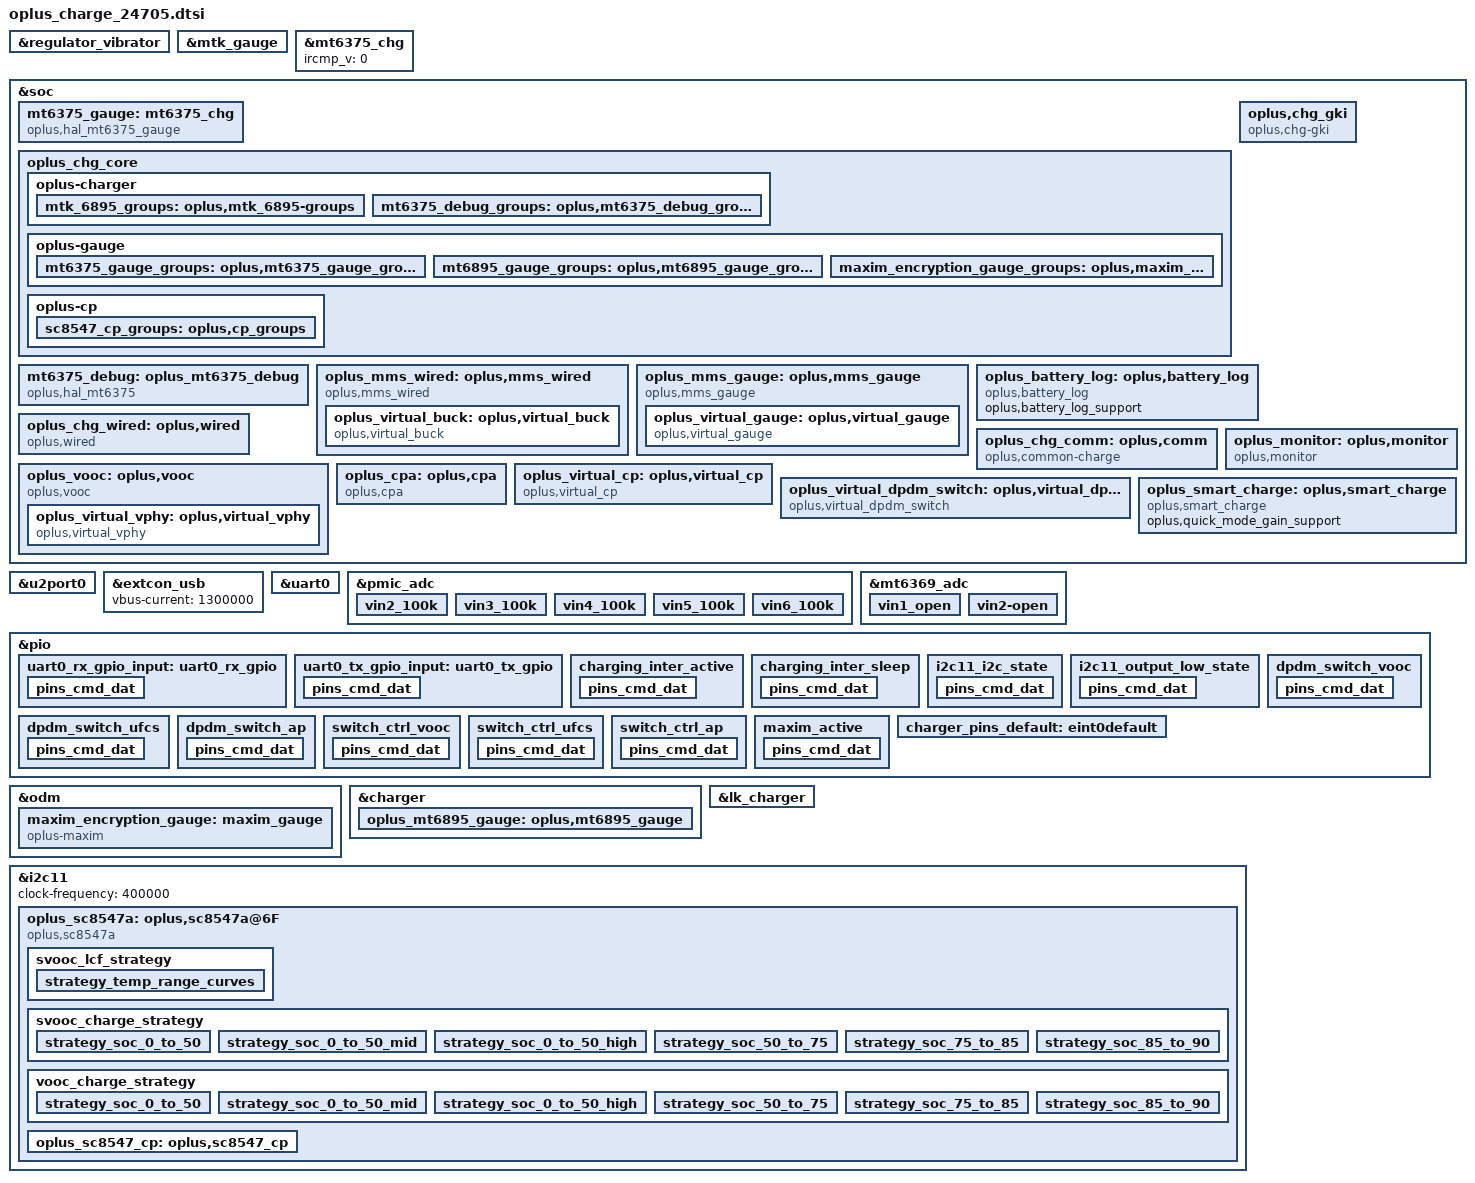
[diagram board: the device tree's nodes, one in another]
// SPDX-License-Identifier: GPL-2.0-only
/*
* Copyright (C) 2021-2020 Oplus. All rights reserved.
*/
#include <dt-bindings/iio/mt635x-auxadc.h>
#include <dt-bindings/iio/adc/mediatek,mt6375_auxadc.h>
#include <dt-bindings/pinctrl/mt6373-pinfunc.h>
#include <dt-bindings/pinctrl/mt65xx.h>
#include "oplus_chg.h"

/*
 *
 * CPU:MT6878 CASIO
 *
 * UTXD0 -->GPIO48
 * URXD0 -->GPIO49
 *
 * I2C
 * MASTER_CHG --> I2C5 MT6375
 * CP_MASTER  --> I2C11 SC8547B
 * CP_SLAVE   --> I2C9 SC8547B
 *
 * IRQB
 * EINT_CHG_1 (cp1 irq)               -->GPIO8
 * EINT_CHG_2 (cp2 irq)               -->GPIO9
 *
 * GPIO
 * VBUS_SHORT(防烧口)                 --> MT6369 MOS_CON1 H8
 * USB_SWITCH_1(usb/uart&vooc switch) --> GPIO44
 * USB_SWITCH_2(uart/vooc switch)     --> GPIO153
 * SEC_IC (加密电池GPIO for 80W)      --> GPIO43
 *
 * ADC:
 * MT6369 AUXADC_VIN1 				--> VBAT_BTB (Battery BTB)
 * MT6369 AUXADC_VIN2               --> NTC_USBCON_TEM (USB BTB)
 *
 * MT6363 AUXADC_VIN2				--> BAT_ID_ADC 电池ID
 * MT6363 AUXADC_VIN3				--> BATThermal_1 小板NTC
 * MT6363 AUXADC_VIN4				--> BB_USB_ADC1 防烧口NTC1
 * MT6363 AUXADC_VIN5				--> BB_USB_ADC2 防烧口NTC2
 * MT6363 AUXADC_VIN6				--> NTC_CHARGE (充电IC旁)
 *
 */

/* charge start */
&regulator_vibrator{
	min-volt = <2800000>;
	max-volt = <2800000>;
};

&mtk_gauge {
	status = "okay";
	charger = <&mt6375_chg>;
	FUELGAGUE_APPLY = <(1)>;
	IS_SUBBOARD_TEMP_SUPPORT = <(0)>;
	EXTERNAL_AUTHENTICATE =<(1)>;
	Enable_Is_Force_Full = <(1)>;
	active-table = <(5)>;
	r-fg-value = <(5)>;/* R_sense resistance. 2 milliohm */
	com-r-fg-value = <(0)>;/* R_sense compensate resistance. not use COM_R_FG_VALUE */
	UNIT_MULTIPLE = <(1)>;
	RBAT_PULL_DOWN_R = <(24000)>;
	RBAT_PULL_UP_R = <(12000)>;
	RBAT_PULL_UP_VOLT = <(1840)>;
	USE_MORE_PRECISE_NTC_TABLE = <(1)>;
	car-tune-value = <(98)>;
	SHUTDOWN_1_TIME = <(5)>;

	io-channels = <&mt6375_auxadc MT6375_AUXADC_BATSNS>,
				  <&mt6375_auxadc MT6375_AUXADC_BATON>,
				  <&mt6375_auxadc MT6375_AUXADC_IMP>,
				  <&mt6375_auxadc MT6375_AUXADC_IMIX_R>,
				  <&mt6375_auxadc MT6375_AUXADC_VREF>,
				  <&pmic_adc AUXADC_VIN2>;
	io-channel-names = "bat_volt", "bat_temp", "ptim_bat_volt",
					   "ptim_r", "vref", "auxadc5-batt_id_v";

	#include "bat_setting/mt6878_battery_prop_dim2_ext_24705.dtsi"
	#include "bat_setting/mt6878_battery_table_24705.dtsi"
};

&mt6375_chg {
	ircmp_v = <0>;
};

&soc {
	mt6375_gauge: mt6375_chg {
		status = "okay";
		compatible = "oplus,hal_mt6375_gauge";

		oplus,ic_type = <OPLUS_CHG_IC_GAUGE>;
		oplus,ic_index = <0>;
		oplus,batt_num = <1>;
		oplus,mtk_gauge_power_sel_support;
	};
};

&u2port0 {
	mediatek,eye-vrt = <7>;
	mediatek,eye-term = <7>;
	mediatek,rev6 = <3>;
	mediatek,eye-vrt-host = <7>;
	mediatek,eye-term-host = <2>;
	mediatek,rev6-host = <3>;
	mediatek,discth = <0x9>;
};

&extcon_usb {
	vbus-current = <1300000>;
};

&uart0 {
	pinctrl-names = "uart0_rx_gpio", "uart0_tx_gpio";
	pinctrl-0 = <&uart0_rx_gpio_input>;
	pinctrl-1 = <&uart0_tx_gpio_input>;
	status = "okay";
	txpin = <48>;
	rxpin = <49>;
};

&pmic_adc {
	vin2_100k {
		channel = <AUXADC_VIN2>;
		pures = <ADC_PURES_100K>;
	};
	vin3_100k {
		channel = <AUXADC_VIN3>;
		pures = <ADC_PURES_100K>;
	};
	vin4_100k {
		channel = <AUXADC_VIN4>;
		pures = <ADC_PURES_100K>;
	};
	vin5_100k {
		channel = <AUXADC_VIN5>;
		pures = <ADC_PURES_100K>;
	};
	vin6_100k {
		channel = <AUXADC_VIN6>;
		pures = <ADC_PURES_100K>;
	};
};

&mt6369_adc {
    vin1_open {
		channel = <AUXADC_VIN1>;
		pures = <ADC_PURES_OPEN>;
    };
	vin2-open {
		channel = <AUXADC_VIN2>;
		pures = <ADC_PURES_OPEN>;
	};
};

&pio {
	uart0_rx_gpio_input: uart0_rx_gpio {
		pins_cmd_dat {
			pinmux = <PINMUX_GPIO49__FUNC_GPIO49>; /* URXD0 */
			input-enable;
			bias-disable;
		};
	};

	uart0_tx_gpio_input: uart0_tx_gpio {
		pins_cmd_dat {
			pinmux = <PINMUX_GPIO48__FUNC_GPIO48>; /* UTXD0 */
			input-enable;
			bias-disable;
		};
	};

	charging_inter_active: charging_inter_active {
		pins_cmd_dat {
			pinmux = <PINMUX_GPIO8__FUNC_GPIO8>;
			input-enable;
			bias-pull-up;
		};
	};

	charging_inter_sleep: charging_inter_sleep {
		pins_cmd_dat {
			pinmux = <PINMUX_GPIO8__FUNC_GPIO8>;
			input-enable;
			bias-pull-up;
		};
	};

	i2c11_i2c_state: i2c11_i2c_state {
		pins_cmd_dat {
			pinmux = <PINMUX_GPIO148__FUNC_SDA11>,
				 <PINMUX_GPIO147__FUNC_SCL11>;
			bias-disable;
		};
	};

	i2c11_output_low_state: i2c11_output_low_state {
		pins_cmd_dat {
			pinmux = <PINMUX_GPIO148__FUNC_GPIO148>,
				 <PINMUX_GPIO147__FUNC_GPIO147>;
			output-low;
		};
	};

	dpdm_switch_vooc: dpdm_switch_vooc {
		pins_cmd_dat {
			pinmux = <PINMUX_GPIO44__FUNC_GPIO44>;
			output-high;
		};
 	};

 	dpdm_switch_ufcs: dpdm_switch_ufcs {
 		pins_cmd_dat {
			pinmux = <PINMUX_GPIO44__FUNC_GPIO44>;
			output-high;
		};
 	};

 	dpdm_switch_ap: dpdm_switch_ap {
 		pins_cmd_dat {
			pinmux = <PINMUX_GPIO44__FUNC_GPIO44>;
			output-low;
		};
 	};

 	switch_ctrl_vooc: switch_ctrl_vooc {
 		pins_cmd_dat {
			pinmux = <PINMUX_GPIO153__FUNC_GPIO153>;
			output-high;
		};
 	};

 	switch_ctrl_ufcs: switch_ctrl_ufcs {
 		pins_cmd_dat {
			pinmux = <PINMUX_GPIO153__FUNC_GPIO153>;
			output-high;
		};
 	};

 	switch_ctrl_ap: switch_ctrl_ap {
 		pins_cmd_dat {
			pinmux = <PINMUX_GPIO153__FUNC_GPIO153>;
			output-low;
		};
 	};

	maxim_active: maxim_active {
		pins_cmd_dat {
			pinmux = <PINMUX_GPIO43__FUNC_GPIO43>;
			drive-strength = <6>;
			bias-pull-up;
		};
	};

	charger_pins_default: eint0default {
	};
};

&soc {
	oplus_chg_core {
		oplus,chg_framework_v2;
		oplus,smart_charging_screenoff;
		oplus,chg_spec_version = <OPLUS_CHG_SPEC_VER_V3P7>;

		oplus-charger {
			mtk_6895_groups: oplus,mtk_6895-groups {
				functions = <
					OPLUS_IC_FUNC_INIT
					OPLUS_IC_FUNC_EXIT
					OPLUS_IC_FUNC_REG_DUMP
					OPLUS_IC_FUNC_SMT_TEST
					OPLUS_IC_FUNC_BUCK_INPUT_PRESENT
					OPLUS_IC_FUNC_BUCK_INPUT_SUSPEND
					OPLUS_IC_FUNC_BUCK_INPUT_IS_SUSPEND
					OPLUS_IC_FUNC_BUCK_OUTPUT_SUSPEND
					OPLUS_IC_FUNC_BUCK_OUTPUT_IS_SUSPEND
					OPLUS_IC_FUNC_BUCK_SET_ICL
					OPLUS_IC_FUNC_BUCK_GET_ICL
					OPLUS_IC_FUNC_BUCK_SET_FCC
					OPLUS_IC_FUNC_BUCK_SET_FV
					OPLUS_IC_FUNC_BUCK_SET_ITERM
					OPLUS_IC_FUNC_BUCK_GET_INPUT_CURR
					OPLUS_IC_FUNC_BUCK_GET_INPUT_VOL
					OPLUS_IC_FUNC_OTG_BOOST_ENABLE
					OPLUS_IC_FUNC_BUCK_GET_CC_ORIENTATION
					OPLUS_IC_FUNC_BUCK_GET_CHARGER_TYPE
					OPLUS_IC_FUNC_BUCK_RERUN_BC12
					OPLUS_IC_FUNC_BUCK_QC_DETECT_ENABLE
					OPLUS_IC_FUNC_BUCK_SET_QC_CONFIG
					OPLUS_IC_FUNC_BUCK_SET_PD_CONFIG
					OPLUS_IC_FUNC_GET_SHUTDOWN_SOC
					OPLUS_IC_FUNC_BACKUP_SOC
					OPLUS_IC_FUNC_GET_TYPEC_MODE
					OPLUS_IC_FUNC_SET_TYPEC_MODE
					OPLUS_IC_FUNC_GET_TYPEC_ROLE
					OPLUS_IC_FUNC_GET_OTG_ENABLE
					OPLUS_IC_FUNC_BUCK_GET_HW_DETECT
					OPLUS_IC_FUNC_SET_USB_DISCHG_ENABLE
					OPLUS_IC_FUNC_GET_USB_DISCHG_STATUS
					OPLUS_IC_FUNC_IS_OPLUS_SVID
					OPLUS_IC_FUNC_BUCK_GET_USB_BTB_TEMP
					OPLUS_IC_FUNC_BUCK_GET_BATT_BTB_TEMP
					OPLUS_IC_FUNC_BUCK_SHIPMODE_ENABLE
					OPLUS_IC_FUNC_BUCK_SET_AICL_POINT
					OPLUS_IC_FUNC_SET_OTG_BOOST_CURR_LIMIT
					OPLUS_IC_FUNC_BUCK_GET_FV
					OPLUS_IC_FUNC_BUCK_GET_TYPEC_STATE
				>;
				virqs = <
					OPLUS_IC_VIRQ_ERR
					OPLUS_IC_VIRQ_CC_DETECT
					OPLUS_IC_VIRQ_PLUGIN
					OPLUS_IC_VIRQ_CC_CHANGED
					OPLUS_IC_VIRQ_CHG_TYPE_CHANGE
					OPLUS_IC_VIRQ_OTG_ENABLE
					OPLUS_IC_VIRQ_SVID
					OPLUS_IC_VIRQ_TYPEC_STATE
				>;
			};


			mt6375_debug_groups: oplus,mt6375_debug_groups {
				functions = <
					OPLUS_IC_FUNC_INIT
					OPLUS_IC_FUNC_EXIT
				>;
				virqs = <
					OPLUS_IC_VIRQ_ERR
				>;
			};
		};

		oplus-gauge {
			mt6375_gauge_groups: oplus,mt6375_gauge_groups {
				functions = <
					OPLUS_IC_FUNC_INIT
					OPLUS_IC_FUNC_EXIT
					OPLUS_IC_FUNC_REG_DUMP
					OPLUS_IC_FUNC_SMT_TEST
					OPLUS_IC_FUNC_GAUGE_GET_BATT_VOL
					OPLUS_IC_FUNC_GAUGE_GET_BATT_MAX
					OPLUS_IC_FUNC_GAUGE_GET_BATT_MIN
					OPLUS_IC_FUNC_GAUGE_GET_BATT_CURR
					OPLUS_IC_FUNC_GAUGE_GET_BATT_TEMP
					OPLUS_IC_FUNC_GAUGE_GET_BATT_SOC
					OPLUS_IC_FUNC_GAUGE_GET_BATT_FCC
					OPLUS_IC_FUNC_GAUGE_GET_BATT_CC
					OPLUS_IC_FUNC_GAUGE_GET_BATT_RM
					OPLUS_IC_FUNC_GAUGE_GET_BATT_SOH
					OPLUS_IC_FUNC_GAUGE_GET_BATT_HMAC
					OPLUS_IC_FUNC_GAUGE_SET_BATT_FULL
					OPLUS_IC_FUNC_GAUGE_UPDATE_DOD0
					OPLUS_IC_FUNC_GAUGE_UPDATE_SOC_SMOOTH
					OPLUS_IC_FUNC_GAUGE_GET_CB_STATUS
					OPLUS_IC_FUNC_GAUGE_GET_BATT_NUM
					OPLUS_IC_FUNC_GAUGE_GET_DEVICE_TYPE
					OPLUS_IC_FUNC_GAUGE_GET_DEVICE_TYPE_FOR_VOOC
					OPLUS_IC_FUNC_GAUGE_GET_BATT_FCC
					OPLUS_IC_FUNC_GAUGE_GET_BATT_FC
					OPLUS_IC_FUNC_GAUGE_GET_BATT_QM
					OPLUS_IC_FUNC_GAUGE_GET_BATT_PD
					OPLUS_IC_FUNC_GAUGE_GET_BATT_RCU
					OPLUS_IC_FUNC_GAUGE_GET_BATT_RCF
					OPLUS_IC_FUNC_GAUGE_GET_BATT_FCU
					OPLUS_IC_FUNC_GAUGE_GET_BATT_FCF
					OPLUS_IC_FUNC_GAUGE_GET_BATT_SOU
					OPLUS_IC_FUNC_GAUGE_GET_BATT_DO0
					OPLUS_IC_FUNC_GAUGE_GET_BATT_DOE
					OPLUS_IC_FUNC_GAUGE_GET_BATT_TRM
					OPLUS_IC_FUNC_GAUGE_GET_BATT_PC
					OPLUS_IC_FUNC_GAUGE_GET_BATT_QS
					OPLUS_IC_FUNC_GAUGE_IS_SUSPEND
					OPLUS_IC_FUNC_GAUGE_GET_BCC_PARMS
					OPLUS_IC_FUNC_GAUGE_FASTCHG_UPDATE_BCC_PARMS
					OPLUS_IC_FUNC_GAUGE_GET_PREV_BCC_PARMS
					OPLUS_IC_FUNC_GAUGE_SET_BCC_PARMS
					OPLUS_IC_FUNC_GAUGE_SET_PROTECT_CHECK
					OPLUS_IC_FUNC_GAUGE_GET_AFI_UPDATE_DONE
					OPLUS_IC_FUNC_GAUGE_CHECK_RESET
					OPLUS_IC_FUNC_GAUGE_GET_DEVICE_TYPE_FOR_BCC
					OPLUS_IC_FUNC_GAUGE_GET_DOD0
					OPLUS_IC_FUNC_GAUGE_GET_DOD0_PASSED_Q
					OPLUS_IC_FUNC_GAUGE_GET_QMAX
					OPLUS_IC_FUNC_GAUGE_GET_QMAX_PASSED_Q
					OPLUS_IC_FUNC_GAUGE_SET_BATTERY_CURVE
				>;
				virqs = <
					OPLUS_IC_VIRQ_ERR
					OPLUS_IC_VIRQ_OFFLINE
					OPLUS_IC_VIRQ_RESUME
				>;
			};

			mt6895_gauge_groups: oplus,mt6895_gauge_groups {
				functions = <
					OPLUS_IC_FUNC_INIT
					OPLUS_IC_FUNC_EXIT
					OPLUS_IC_FUNC_GAUGE_GET_SUBBOARD_TEMP
				>;
				virqs = <
					OPLUS_IC_VIRQ_ERR
				>;
			};

			maxim_encryption_gauge_groups: oplus,maxim_encryption_gauge_groups {
				functions = <
					OPLUS_IC_FUNC_INIT
					OPLUS_IC_FUNC_EXIT
					OPLUS_IC_FUNC_GAUGE_GET_BATT_AUTH
				>;
				virqs = <
					OPLUS_IC_VIRQ_ERR
				>;
			};
		};
		oplus-cp {
			sc8547_cp_groups: oplus,cp_groups {
			functions = <
					OPLUS_IC_FUNC_INIT
					OPLUS_IC_FUNC_EXIT
					OPLUS_IC_FUNC_REG_DUMP
					OPLUS_IC_FUNC_SMT_TEST
					OPLUS_IC_FUNC_CP_ENABLE
					OPLUS_IC_FUNC_CP_HW_INTI
					OPLUS_IC_FUNC_CP_SET_WORK_START
					OPLUS_IC_FUNC_CP_CHECK_WORK_MODE_SUPPORT
					OPLUS_IC_FUNC_CP_SET_WORK_MODE
					OPLUS_IC_FUNC_CP_GET_WORK_MODE
					OPLUS_IC_FUNC_CP_GET_VIN
					OPLUS_IC_FUNC_CP_GET_IIN
					OPLUS_IC_FUNC_CP_SET_IIN
					OPLUS_IC_FUNC_CP_GET_VOUT
					OPLUS_IC_FUNC_CP_GET_IOUT
					OPLUS_IC_FUNC_CP_GET_VAC
					OPLUS_IC_FUNC_CP_GET_WORK_STATUS
					OPLUS_IC_FUNC_CP_SET_ADC_ENABLE
					OPLUS_IC_FUNC_CP_WATCHDOG_ENABLE
				>;
				virqs = <
					OPLUS_IC_VIRQ_ERR
					OPLUS_IC_VIRQ_ONLINE
					OPLUS_IC_VIRQ_OFFLINE
				>;
			};
		};
	};
};

&soc {
	mt6375_debug: oplus_mt6375_debug {
		status = "okay";
		compatible = "oplus,hal_mt6375";

		oplus,tcpc_name = "type_c_port0";

		oplus,ic_type = <OPLUS_CHG_IC_BUCK>;
		oplus,ic_index = <2>;
	};
};

&odm {
	maxim_encryption_gauge: maxim_gauge {
		status = "okay";
		compatible = "oplus-maxim";
		pinctrl-names = "maxim_active";
		pinctrl-0 = <&maxim_active>;
		support_encryption_in_lk;
		data-gpio = <&pio 43 0x00>;
		gpio-addr-set-out = <0x10005014>;
		gpio-addr-set-in = <0x10005018>;
		gpio-addr-level_high = <0x10005114>;
		gpio-addr-level_low = <0x10005118>;
		gpio-addr-data-in = <0x10005210>;
		gpio-addr-offset = <0x0b>;
		oplus,batt_info = /bits/ 8 <0x36 0x31 0x31 0x33 0x30 0x33 0x30 0x30 0x30 0x30 0x36 0x33
		                            0x36 0x31 0x31 0x33 0x30 0x33 0x30 0x30 0x30 0x30 0x36 0x34
		                            0x36 0x31 0x31 0x33 0x30 0x33 0x30 0x30 0x30 0x31 0x37 0x31
		                            0x36 0x31 0x31 0x33 0x30 0x33 0x30 0x30 0x30 0x31 0x37 0x32>;
		oplus,ic_type = <OPLUS_CHG_IC_GAUGE>;
		oplus,ic_index = <2>;
	};
};

&soc {
	oplus,chg_gki {
		compatible = "oplus,chg-gki";
	};
};

&charger {
	io-channels = <&mt6369_adc (ADC_PURES_OPEN_MASK | AUXADC_VIN1)>, <&mt6369_adc (ADC_PURES_OPEN_MASK | AUXADC_VIN2)>, <&pmic_adc AUXADC_VIN6>, <&pmic_adc AUXADC_VIN3>;
	io-channel-names = "auxadc5_batt_btb_temp", "auxadc6_usb_btb_temp", "auxadc5-chargeric_temp", "auxadc1-ntc_sub_bat_tem";

	pinctrl-names = "default";
	pinctrl-0 = <&charger_pins_default>;
	oplus,support_ntc_01c_precision;
	max_charger_voltage = <15000000>;
	oplus,ntc_temp_volt_1840mv;
	oplus,force_use_4250K_ntc;

	/* usbtemp dischg use pmic regulator to set vbus down */
	oplus,support_usbtemp_dischg_reg_configurable;
	oplus,usbtemp_dischg_reg_addr = <0x989>;
	oplus,usbtemp_dischg_reg_mask = <0x7>;
	oplus,usbtemp_dischg_enable = <0x2>;
	oplus,usbtemp_dischg_disable = <0x0>;

	oplus,ic_type = <OPLUS_CHG_IC_BUCK>;
	oplus,ic_index = <0>;

	oplus_mt6895_gauge: oplus,mt6895_gauge {
		oplus,ic_type = <OPLUS_CHG_IC_GAUGE>;
		oplus,ic_index = <1>;
	};
};

&lk_charger {
	en_vol_ctrl_vibrate = <3200>;
	support_tuv_authentication;
	high-temp-scheme;
	charger_no_wiress;
	support_battery_type = <2>;
	support_maxim_battery_authentication;
	data-gpio = <43>;
	oplus,batt_info = /bits/ 8 <0x36 0x31 0x31 0x33 0x30 0x33 0x30 0x30 0x30 0x30 0x36 0x33
			                    0x36 0x31 0x31 0x33 0x30 0x33 0x30 0x30 0x30 0x30 0x36 0x34
			                    0x36 0x31 0x31 0x33 0x30 0x33 0x30 0x30 0x30 0x31 0x37 0x31
			                    0x36 0x31 0x31 0x33 0x30 0x33 0x30 0x30 0x30 0x31 0x37 0x32>;

	support_sdp_screenoff;
	sdp_screenon_voltage = <3250>;
	support_quickboot_charge;
    support_hot_enter_kpoc;
    over_high_temp_thr = <60>;

	led-brightness = <102>;
	max-charger-voltage = <15000000>;
	boot-battery-voltage = <3350000>;
	usb-charger-current = <500000>;
	ac-charger-current = <2050000>;
	ac-charger-input-current = <1500000>;
	non-std-ac-charger-current = <750000>;
	charging-host-charger-current = <1500000>;
	ta-ac-charger-current = <1500000>;
	pd-charger-current = <500000>;
};

&soc {
	oplus_mms_wired: oplus,mms_wired {
		compatible = "oplus,mms_wired";
		oplus,buck_ic = <&oplus_virtual_buck>;
		oplus,voocphy_ic = <&oplus_virtual_vphy>;
		oplus,adc_info_name = "100k_1840mv";
		oplus_spec,usbtemp_batttemp_gap = <12>;

		/* support for V2.0 usbtemp protect. */
		oplus,support_usbtemp_protect_v2;
		oplus_spec,usbtemp_batt_temp_low = <50>;
		oplus_spec,usbtemp_batt_temp_high = <50>;
		oplus_spec,usbtemp_batt_temp_over_hot = <60>;
		oplus_spec,usbtemp_ntc_temp_low = <57>;
		oplus_spec,usbtemp_ntc_temp_high = <69>;
		oplus_spec,usbtemp_temp_gap_low_with_batt_temp = <7>;
		oplus_spec,usbtemp_temp_gap_with_batt_temp_in_over_hot = <15>;
		oplus_spec,usbtemp_temp_gap_high_with_batt_temp = <12>;
		oplus_spec,usbtemp_temp_gap_low_without_batt_temp = <12>;
		oplus_spec,usbtemp_temp_gap_high_without_batt_temp = <24>;
		oplus_spec.usbtemp_rise_fast_temp_low = <3>;
		oplus_spec.usbtemp_rise_fast_temp_high = <3>;
		oplus_spec.usbtemp_rise_fast_temp_count_low = <30>;
		oplus_spec.usbtemp_rise_fast_temp_count_high = <20>;
		oplus_spec,usbtemp_cool_down_ntc_low = <54>;
		oplus_spec,usbtemp_cool_down_ntc_high = <65>;
		oplus_spec,usbtemp_cool_down_gap_low = <12>;
		oplus_spec,usbtemp_cool_down_gap_high = <20>;
		oplus_spec,usbtemp_cool_down_recover_ntc_low = <48>;
		oplus_spec,usbtemp_cool_down_recover_ntc_high = <60>;
		oplus_spec,usbtemp_cool_down_recover_gap_low = <6>;
		oplus_spec,usbtemp_cool_down_recover_gap_high = <15>;

		oplus_virtual_buck: oplus,virtual_buck {
			compatible = "oplus,virtual_buck";
			oplus,buck_ic = <&charger &mt6375_debug>;
			oplus,buck_ic_index = <0 1>;
			oplus,buck_ic_current_ratio = <100 0>;
			oplus,buck_ic_connect = <OPLUS_CHG_IC_CONNECT_PARALLEL>;
			oplus,main_charger = <0>;
			oplus,buck_ic_func_group = <&mtk_6895_groups &mt6375_debug_groups>;

			oplus,ic_type = <OPLUS_CHG_IC_VIRTUAL_BUCK>;
			oplus,ic_index = <0>;

			io-channels = <&pmic_adc AUXADC_VIN4>, <&pmic_adc AUXADC_VIN5>;
			io-channel-names = "usb_temp_adc_l", "usb_temp_adc_r";

			oplus,uart_tx-gpio = <&pio 48 0x00>;
			oplus,uart_rx-gpio = <&pio 49 0x00>;
		};
	};

	oplus_mms_gauge: oplus,mms_gauge {
		compatible = "oplus,mms_gauge";
		oplus,gauge_ic = <&oplus_virtual_gauge>;
		oplus,voocphy_ic = <&oplus_virtual_vphy>;
		oplus,topic-update-interval = <10000>;

		oplus_virtual_gauge: oplus,virtual_gauge {
			compatible = "oplus,virtual_gauge";
			oplus,gauge_ic = <&mt6375_gauge &oplus_mt6895_gauge &maxim_encryption_gauge>;
			oplus,gauge_ic_index = <0 1 2>;
			oplus,gauge_ic_func_group = <&mt6375_gauge_groups &mt6895_gauge_groups &maxim_encryption_gauge_groups>;
			oplus,batt_capacity_mah = <6000>;
			oplus,ic_type = <OPLUS_CHG_IC_VIRTUAL_GAUGE>;
			oplus,ic_index = <0>;
		};
	};
};

&soc {
	oplus_battery_log: oplus,battery_log {
		compatible = "oplus,battery_log";

		oplus,battery_log_support;
	};

	oplus_chg_wired: oplus,wired {
		compatible = "oplus,wired";

		oplus,vooc-support;

		oplus_spec,vbatt_pdqc_to_5v_thr = <4470>;
		oplus_spec,vbatt_pdqc_to_9v_thr = <4500>;
		oplus_spec,pd-iclmax-ma = <2000>;
		oplus_spec,qc-iclmax-ma = <2000>;
		oplus_spec,non-standard-ibatmax-ma = <500>;
		oplus_spec,input-power-mw = <
			2500		/* OPLUS_WIRED_CHG_MODE_UNKNOWN */
			2500		/* OPLUS_WIRED_CHG_MODE_SDP */
			7500		/* OPLUS_WIRED_CHG_MODE_CDP */
			10000		/* OPLUS_WIRED_CHG_MODE_DCP */
			18000		/* OPLUS_WIRED_CHG_MODE_VOOC */
			18000		/* OPLUS_WIRED_CHG_MODE_QC */
			18000		/* OPLUS_WIRED_CHG_MODE_PD */
		>;
		oplus_spec,led_on-fccmax-ma = <0 1140 4000 4000 4000 4000 4000 1000 0>;
		oplus_spec,fccmax-ma-lv = <
			0 731  2200 2200 2200 2200 2200 2200 0	/* OPLUS_WIRED_CHG_MODE_UNKNOWN */
			0 600  600  600  600  600  600  600  0	/* OPLUS_WIRED_CHG_MODE_SDP */
			0 731  1600 1600 1600 1600 1600 1600 0	/* OPLUS_WIRED_CHG_MODE_CDP */
			0 731  2200 2200 2200 2200 2200 2200 0	/* OPLUS_WIRED_CHG_MODE_DCP */
			0 1250 3000 3000 3000 3000 3000 2200 0	/* OPLUS_WIRED_CHG_MODE_VOOC */
			0 731  3166 3300 3300 3300 3300 2679 0	/* OPLUS_WIRED_CHG_MODE_QC */
			0 731  3166 3300 3300 3300 3300 2679 0	/* OPLUS_WIRED_CHG_MODE_PD */
		>;
		oplus_spec,fccmax-ma-hv = <
			0 731  2200 2200 2200 2200 2200 2200 0	/* OPLUS_WIRED_CHG_MODE_UNKNOWN */
			0 600  600  600  600  600  600  600  0	/* OPLUS_WIRED_CHG_MODE_SDP */
			0 731  1600 1600 1600 1600 1600 1600 0	/* OPLUS_WIRED_CHG_MODE_CDP */
			0 731  2200 2200 2200 2200 2200 2200 0	/* OPLUS_WIRED_CHG_MODE_DCP */
			0 1250 3000 3000 3000 3000 3000 2200 0	/* OPLUS_WIRED_CHG_MODE_VOOC */
			0 731  3166 3300 3300 3300 3300 2679 0	/* OPLUS_WIRED_CHG_MODE_QC */
			0 731  3166 3300 3300 3300 3300 2679 0	/* OPLUS_WIRED_CHG_MODE_PD */
		>;

		oplus_spec,cool_down_pdqc_vol_mv = <9000 9000 9000>;
		oplus_spec,cool_down_pdqc_curr_ma = <1200 1500 2000>;
		oplus_spec,cool_down_vooc_curr_ma = <1200 1500 2000 2500 3000 3000>;
		oplus_spec,cool_down_normal_curr_ma = <1200 1500 2000>;

		oplus_spec,vbus_ov_thr_mv = <11000 11000>;
		oplus_spec,vbus_uv_thr_mv = <4300 4300>;

		/* first data is strategy used temp type */
		oplus,vooc_strategy_name = "cgcl";
		oplus,vooc_strategy_data = <OPLUS_STRATEGY_USE_BATT_TEMP
					    0   385 3000 1 0
					    385 420 3000 2 0
					    420 440 2000 2 1>;
	};

	oplus_chg_comm: oplus,comm {
		compatible = "oplus,common-charge";
		oplus_spec,batt-them-thr = <(-100) 0 50 120 160 350 450 530>;
		oplus_spec,iterm-ma = <260>; /* 5000*0.05+10 */
		oplus_spec,removed_bat_decidegc = <390>; /*-39 degree*/
		oplus_spec,fv-mv = <4470 4470 4470 4470 4470 4470 4470 4130 4130>;
		oplus_spec,sw-fv-mv = <4420 4420 4420 4420 4420 4420 4420 4080 4080>;
		oplus_spec,hw-fv-inc-mv = <0 18 18 18 18 18 18 18 0>;
		oplus_spec,sw-over-fv-mv = <4480 4480 4480 4480 4480 4480 4480 4140 4140>;
		oplus_spec,sw-over-fv-dec-mv = <8>;
		oplus_spec,non-standard-sw-fv-mv = <3930>;
		oplus_spec,non-standard-fv-mv = <3980>;
		oplus_spec,non-standard-hw-fv-inc-mv = <18>;
		oplus_spec,non-standard-sw-over-fv-mv = <3990>;
		oplus_spec,non-standard-vbatdet-mv = <3680>;
		oplus_spec,wired-vbatdet-mv = <0 4170 4270 4370 4370 4370 4370 4030 0>;
		oplus_spec,fcc-gear-thr-mv = <4180>;
		oplus_spec,vbatt-ov-thr-mv = <4600>;

		oplus_spec,full_pre_ffc_judge;
		oplus_spec,full-pre-ffc-mv = <4465>;
		oplus_spec,ffc-temp-thr = <120 200 350 400>;
		oplus_spec,wired-ffc-step-max = <2>;
		oplus_spec,wired-ffc-fv-mv = <4600 4600>;

		oplus_spec,wired-ffc-fv-cutoff-mv = <4515 4515 4515 4515 4515 4515>;
		oplus_spec,wired-ffc-fcc-ma = <1500 1500 1500 750 900 950>;
		oplus_spec,wired-ffc-fcc-cutoff-ma = <1300 1300 1300 650 800 850>;
		oplus_spec,vbat_uv_thr_mv = <3300>;
		oplus_spec,vbat_charging_uv_thr_mv = <3200>;

		/*If use subboard NTC as battery temp, config it as 20, otherwise 0 */
		oplus_spec,tbatt_power_off_cali_temp = <0>;
		oplus_spec,poweroff_high_batt_temp = <720>;
		oplus_spec,poweroff_emergency_batt_temp = <770>;
		oplus,vooc_show_ui_soc_decimal;
		oplus,ui_soc_decimal_speedmin = <20>;
		oplus,gauge_stuck_jump_support;
		oplus,gauge_stuck_threshold = <15>;
		oplus,gauge_stuck_time = <50>;
	};

	oplus_monitor: oplus,monitor {
		compatible = "oplus,monitor";
		oplus,topic-update-interval = <60000>;

		track,fast_chg_break_t_thd = <1000>;
		track,general_chg_break_t_thd = <200>;
		track,voocphy_type = <2>;
		track,wired_max_power = <45000>;
		track,wired_fast_chg_scheme = <2>;
	};

	oplus_vooc: oplus,vooc {
		compatible = "oplus,vooc";
		oplus,vooc_ic = <&oplus_virtual_vphy>;

		oplus_spec,vooc_soc_range = <50 75 85>;

		oplus,vooc_data_width = <7>;
		oplus,vooc_curr_max = <CP_CURR_LIMIT_7BIT_9_0A>; /* 45W: 11V 7.3A(IBUS *2) */
		oplus,vooc_power_max_w = <45>;
		oplus,vooc_project = <21>;
		oplus,vooc_curr_table_type = <VOOC_CP_CURR_TABLE>;
		oplus,voocphy_support = <2>; /* AP_SINGLE_CP_VOOCPHY */
		oplus,support_fake_vooc_check;
		oplus,subboard_ntc_abnormal_current = <4000>;

		oplus,abnormal_adapter_current = <CURR_LIMIT_7BIT_7_5A CURR_LIMIT_7BIT_7_5A
						CURR_LIMIT_7BIT_5_0A CURR_LIMIT_7BIT_5_0A
						CURR_LIMIT_7BIT_4_0A CURR_LIMIT_7BIT_4_0A
						CURR_LIMIT_7BIT_3_0A CURR_LIMIT_7BIT_3_0A
						CURR_LIMIT_7BIT_2_0A CURR_LIMIT_7BIT_2_0A>;

		/* first data is strategy used temp type */
		oplus,general_strategy_name = "cgcl";
		oplus,general_strategy_data = < OPLUS_STRATEGY_USE_SHELL_TEMP
						0   400 CURR_LIMIT_7BIT_7_5A 1 0
						390 420 CURR_LIMIT_7BIT_5_0A 2 0
						410 430 CURR_LIMIT_7BIT_4_0A 3 1
						420 440 CURR_LIMIT_7BIT_3_0A 3 2 >;


		oplus_virtual_vphy: oplus,virtual_vphy {
			compatible = "oplus,virtual_vphy";
			oplus,vphy_ic = <&oplus_sc8547a>;

			oplus,ic_type = <OPLUS_CHG_IC_VIRTUAL_VPHY>;
			oplus,ic_index = <0>;
			oplus,dpdm_switch_ic = <&oplus_virtual_dpdm_switch>;
		};
	};

	oplus_cpa: oplus,cpa {
		compatible = "oplus,cpa";
		oplus,protocol_list = <CHG_PROTOCOL_VOOC 45
						CHG_PROTOCOL_PPS  45
				       CHG_PROTOCOL_PD 18
				       CHG_PROTOCOL_QC 18>;
		oplus,default_protocol_list = <CHG_PROTOCOL_PD
						CHG_PROTOCOL_PPS
					    CHG_PROTOCOL_VOOC>;
	};

	oplus_virtual_cp: oplus,virtual_cp {
		compatible = "oplus,virtual_cp";

		oplus,ic_type = <OPLUS_CHG_IC_VIRTUAL_CP>;
		oplus,ic_index = <0>;

		oplus,cp_ic = <&oplus_sc8547_cp>;
		oplus,input_curr_max_ma = <5000>;
		oplus,main_cp = <0>;
		oplus,cp_ic_connect = <OPLUS_CHG_IC_CONNECT_PARALLEL>;

		oplus,reg_proc_node;
	};

	oplus_virtual_dpdm_switch: oplus,virtual_dpdm_switch {
		compatible = "oplus,virtual_dpdm_switch";
		oplus,ic_type = <OPLUS_CHG_IC_MISC>;
		oplus,ic_index = <0>;

		oplus,switch_ctrl-gpio = <&pio 153 0x00>;
		oplus,dpdm_switch1-gpio = <&pio 44 0x00>;

		pinctrl-names = "switch_ctrl_ap", "switch_ctrl_vooc", "switch_ctrl_ufcs",
						"dpdm_switch_ap", "dpdm_switch_vooc", "dpdm_switch_ufcs";
		pinctrl-0 = <&switch_ctrl_ap>;
		pinctrl-1 = <&switch_ctrl_vooc>;
		pinctrl-2 = <&switch_ctrl_ufcs>;
		pinctrl-3 = <&dpdm_switch_ap>;
		pinctrl-4 = <&dpdm_switch_vooc>;
		pinctrl-5 = <&dpdm_switch_ufcs>;
	};
	oplus_smart_charge: oplus,smart_charge {
		compatible = "oplus,smart_charge";
		oplus,quick_mode_gain_support;
	};
};

&i2c11 {
	status = "okay";
	clock-frequency = <400000>;
	oplus_sc8547a: oplus,sc8547a@6F {
		status = "okay";
		compatible = "oplus,sc8547a";
		reg = <0x6F>;

		oplus,use_vooc_phy;
		oplus_spec,irq_gpio = <&pio 8 0x00>;
		interrupt-parent = <&pio>;
		interrupts = <9 0>;

		pinctrl-names = "charging_inter_active", "charging_inter_sleep", "i2c-state", "output-low-state";
		pinctrl-0 = <&charging_inter_active>;
		pinctrl-1 = <&charging_inter_sleep>;
		pinctrl-2 = <&i2c11_i2c_state>;
		pinctrl-3 = <&i2c11_output_low_state>;

		oplus,ic_type = <OPLUS_CHG_IC_VPHY>;
		oplus,ic_index = <0>;
		oplus,vooc-version = <VOOC_VERSION_5_0>;

		ocp_reg = <0xd>;
		ovp_reg = <0x36>;/* vbat ovp 4.85v */
		oplus_spec,slave_cp_enable_thr = <1400>;		//2000-100mA
		oplus_spec,slave_cp_disable_thr_high = <1100>;	//1500+100mA
		oplus_spec,voocphy_current_default = <73>;

		oplus_spec,svooc_cool_down_current_limit = <82 20 20 24 30 34 40 44 50 54 60 64 70 74>;
		oplus_spec,vooc_cool_down_current_limit = <30 20 20 24 30 34 40 44 50 54 60 64 70 74>;

		oplus_spec,vooc_low_temp = <0>;
		oplus_spec,vooc_little_cold_temp = <50>;
		oplus_spec,vooc_cool_temp = <120>;
		oplus_spec,vooc_little_cool_temp = <160>;
		oplus_spec,vooc_little_cool_high_temp = <200>;
		oplus_spec,vooc_normal_low_temp = <350>;
		oplus_spec,vooc_normal_high_temp = <440>;
		oplus_spec,vooc_high_temp = <500>;
		oplus_spec,vooc_over_high_temp = <510>;
		oplus_spec,vooc_strategy_normal_current = <122>;
		oplus_spec,vooc_normal_to_little_cool_current = <100>;
		oplus_spec,vooc_multistep_initial_batt_temp = <1000>;
		oplus_spec,fastchg_timeout_time_init = <150680>;

		oplus_spec,vooc_low_soc = <0>;
		oplus_spec,vooc_high_soc = <95>;
		oplus_spec,vooc_warm_vol_thr = <4000>;
		oplus_spec,vooc_warm_soc_thr = <50>;

		oplus_spec,vooc_strategy1_batt_high_temp0 = <385>;
		oplus_spec,vooc_strategy1_batt_high_temp1 = <395>;
		oplus_spec,vooc_strategy1_batt_high_temp2 = <420>;
		oplus_spec,vooc_strategy1_batt_low_temp2 = <410>;
		oplus_spec,vooc_strategy1_batt_low_temp1 = <385>;
		oplus_spec,vooc_strategy1_batt_low_temp0 = <375>;

		oplus_spec,vooc_strategy1_high_current0 = <80>;
		oplus_spec,vooc_strategy1_high_current1 = <61>;
		oplus_spec,vooc_strategy1_high_current2 = <40>;
		oplus_spec,vooc_strategy1_low_current2 = <40>;
		oplus_spec,vooc_strategy1_low_current1 = <61>;
		oplus_spec,vooc_strategy1_low_current0 = <80>;

		oplus_spec,voocphy_freq_mincore = <1800000>;
		oplus_spec,voocphy_freq_midcore = <1800000>;
		oplus_spec,voocphy_freq_maxcore = <1800000>;
		oplus_spec,voocphy_current_change_timeout = <100>;
		oplus_spec,copycat_vooc_support;
		oplus_spec,copycat_vooc_accuracy_value = <105>;
		oplus,copycat-vooc-count = <4>;

		oplus_spec,voocphy_ibat_over_current = <9700>;
		oplus_spec,voocphy_svooc_cp_max_ibus = <4500>;
		oplus_spec,voocphy_vooc_cp_max_ibus = <4500>;
		oplus_spec,voocphy_cp_max_ibus = <4500>;

		oplus_spec,vooc_little_cold_full_voltage = <4480>;
		oplus_spec,vooc_cool_full_voltage = <4480>;
		oplus_spec,vooc_little_cool_full_voltage = <4520>;
		oplus_spec,vooc_little_cool_high_full_voltage = <4520>;
		oplus_spec,vooc_warm_full_voltage = <4130>;
		oplus_spec,vooc_1time_full_voltage = <4530>;
		oplus_spec,vooc_ntime_full_voltage = <4520>;
		oplus_spec,soc_range = <0 20 35 55 75 85 95>;

		svooc_batt_sys_curve = <0 1 0 1 0 0 0	// 4000mA
					1 1 1 1 0 0 0	// 4604mV
					0 0 1 1 0 1 0	// 2600mA
					1 1 1 1 0 0 0	// 4604mV
					0 0 0 1 0 1 1	// 1100mA
					1 1 1 1 0 0 0>;	// 4604mV

		vooc_batt_sys_curve =  <0 1 0 1 0 0 0	// 4000mA
					1 1 1 1 0 0 0	// 4604mV
					0 0 1 1 0 1 0	// 2600mA
					1 1 1 1 0 0 0	// 4604mV
					0 0 0 1 0 1 1	// 1100mA
					1 1 1 1 0 0 0>;	// 4604mV
		svooc_lcf_strategy {
			oplus,temp_type = <OPLUS_STRATEGY_USE_SHELL_TEMP>;
			oplus,temp_range = <0 50 120 160 200 350 430>;

			strategy_temp_range_curves {
				strategy_temp_range_t0 = <50 4480 0
								 0 4475 0
								 50 4460 0
								 100 4450 0
								 150 4440 1>;
				strategy_temp_range_t1 = <300 4480 0
								 250 4475 0
								 150 4460 0
								 50 4450 0
								 0 4440 1>;
				strategy_temp_range_t2 = <700 4520 0
								 600 4515 0
								 500 4500 0
								 400 4490 0
								 300 4480 1>;
				strategy_temp_range_t3 = <700 4520 0
								 600 4515 0
								 500 4500 0
								 400 4490 0
								 300 4480 1>;
				strategy_temp_range_t4 = <850 4520 0
								 750 4515 0
								 650 4500 0
								 550 4490 0
								 450 4480 1>;
				strategy_temp_range_t5 = <900 4520 0
								 800 4515 0
								 700 4500 0
								 600 4490 0
								 500 4480 1>;
			};
		};

		svooc_charge_strategy {
			strategy_soc_0_to_50 { /* 0 ~ 20 */
				strategy_temp_little_cold =	<4150 15 0 0 0
								 4470 11 0 0 0
								 4480 10 1 0 0>;
				strategy_temp_cool =	<4150 23 0 0 0
								 4150 20 0 0 0
								 4470 15 0 0 0
								 4480 10 1 0 0>;
				strategy_temp_little_cool =	<4150 35 0 0 0
								 4150 30 0 0 0
								 4480 28 0 0 0
								 4480 25 0 0 0
								 4480 20 0 0 0
								 4510 18 0 0 0
								 4510 15 0 0 0
								 4520 10 1 0 0>;
				strategy_temp_little_cool_high = <4150 35 0 0 0
								 4150 30 0 0 0
								 4480 28 0 0 0
								 4480 25 0 0 0
								 4480 20 0 0 0
								 4510 18 0 0 0
								 4510 15 0 0 0
								 4520 10 1 0 0>;
				strategy_temp_normal_low =	<4230 41 0 60 0
								 4230 35 0 0 0
								 4230 30 0 600 0
								 4480 28 0 0 0
								 4480 25 0 600 0
								 4480 20 0 0 0
								 4510 18 0 0 0
								 4510 15 0 0 0
								 4520 10 1 0 0>;
				strategy_temp_normal_high =	<4230 41 0 60 0
								 4230 35 0 0 0
								 4230 30 0 600 0
								 4480 28 0 0 0
								 4480 25 0 600 0
								 4480 20 0 0 0
								 4510 18 0 0 0
								 4510 15 0 0 0
								 4520 10 1 0 0>;
				strategy_temp_warm = <4120 13 0 0 0
								 4130 10 1 0 0>;
			};

			strategy_soc_0_to_50_mid { /* 21 ~ 35 */
				strategy_temp_little_cold =	<4150 15 0 0 0
								 4470 11 0 0 0
								 4480 10 1 0 0>;
				strategy_temp_cool =	<4150 23 0 0 0
								 4150 20 0 0 0
								 4470 15 0 0 0
								 4480 10 1 0 0>;
				strategy_temp_little_cool =	<4150 35 0 0 0
								 4150 30 0 0 0
								 4480 28 0 0 0
								 4480 25 0 0 0
								 4480 20 0 0 0
								 4510 18 0 0 0
								 4510 15 0 0 0
								 4520 10 1 0 0>;
				strategy_temp_little_cool_high = <4150 35 0 0 0
								 4150 30 0 0 0
								 4480 28 0 0 0
								 4480 25 0 0 0
								 4480 20 0 0 0
								 4510 18 0 0 0
								 4510 15 0 0 0
								 4520 10 1 0 0>;
				strategy_temp_normal_low = <4230 41 0 60 0
								 4230 35 0 0 0
								 4230 30 0 600 0
								 4480 28 0 0 0
								 4480 25 0 600 0
								 4480 20 0 0 0
								 4510 18 0 0 0
								 4510 15 0 0 0
								 4520 10 1 0 0>;
				strategy_temp_normal_high =	<4230 41 0 60 0
								 4230 35 0 0 0
								 4230 30 0 600 0
								 4480 28 0 0 0
								 4480 25 0 600 0
								 4480 20 0 0 0
								 4510 18 0 0 0
								 4510 15 0 0 0
								 4520 10 1 0 0>;
				strategy_temp_warm = <4120 13 0 0 0
								 4130 10 1 0 0>;
			};

			strategy_soc_0_to_50_high { /* 36 ~ 55 */
				strategy_temp_little_cold =	<4150 15 0 0 0
								 4470 11 0 0 0
								 4480 10 1 0 0>;
				strategy_temp_cool = <4150 23 0 0 0
								 4150 20 0 0 0
								 4470 15 0 0 0
								 4480 10 1 0 0>;
				strategy_temp_little_cool =	<4150 30 0 0 0
								 4480 28 0 0 0
								 4480 25 0 0 0
								 4480 20 0 0 0
								 4510 18 0 0 0
								 4510 15 0 0 0
								 4520 10 1 0 0>;
				strategy_temp_little_cool_high = <4150 30 0 0 0
								 4480 28 0 0 0
								 4480 25 0 0 0
								 4480 20 0 0 0
								 4510 18 0 0 0
								 4510 15 0 0 0
								 4520 10 1 0 0>;
				strategy_temp_normal_low =	<4230 41 0 60 0
								 4230 35 0 0 0
								 4230 30 0 600 0
								 4480 28 0 0 0
								 4480 25 0 600 0
								 4480 20 0 0 0
								 4510 18 0 0 0
								 4510 15 0 0 0
								 4520 10 1 0 0>;
				strategy_temp_normal_high =	<4230 41 0 60 0
								 4230 35 0 0 0
								 4230 30 0 600 0
								 4480 28 0 0 0
								 4480 25 0 600 0
								 4480 20 0 0 0
								 4510 18 0 0 0
								 4510 15 0 0 0
								 4520 10 1 0 0>;
				strategy_temp_warm = <4120 13 0 0 0
								 4130 10 1 0 0>;
			};

			strategy_soc_50_to_75 { /* 56 ~ 75 */
				strategy_temp_little_cold =	<4480 10 1 0 0>;
				strategy_temp_cool =	<4470 15 0 0 0
								 4480 10 1 0 0>;
				strategy_temp_little_cool =	<4480 20 0 0 0
								 4510 18 0 0 0
								 4510 15 0 0 0
								 4520 10 1 0 0>;
				strategy_temp_little_cool_high = <4480 20 0 0 0
								 4510 18 0 0 0
								 4510 15 0 0 0
								 4520 10 1 0 0>;
				strategy_temp_normal_low =	<4480 25 0 0 0
								 4480 20 0 0 0
								 4510 18 0 0 0
								 4510 15 0 0 0
								 4520 10 1 0 0>;
				strategy_temp_normal_high =	<4480 25 0 0 0
								 4480 20 0 0 0
								 4510 18 0 0 0
								 4510 15 0 0 0
								 4520 10 1 0 0>;
				strategy_temp_warm = <4130 10 1 0 0>;
			};

			strategy_soc_75_to_85 {	/*76 ~ 85*/
				strategy_temp_little_cold =	<4480 10 1 0 0>;
				strategy_temp_cool =	<4480 10 1 0 0>;
				strategy_temp_little_cool =	<4510 15 0 0 0
								 4520 10 1 0 0>;
				strategy_temp_little_cool_high = <4510 15 0 0 0
								 4520 10 1 0 0>;
				strategy_temp_normal_low =	<4510 15 0 0 0
								 4520 10 1 0 0>;
				strategy_temp_normal_high =	<4510 15 0 0 0
								 4520 10 1 0 0>;
				strategy_temp_warm = <4130 10 1 0 0>;
			};

			strategy_soc_85_to_90 { /*86 ~ 95*/
				strategy_temp_little_cold =	<4480 10 1 0 0>;
				strategy_temp_cool =	<4480 10 1 0 0>;
				strategy_temp_little_cool =	<4520 10 1 0 0>;
				strategy_temp_little_cool_high = <4520 10 1 0 0>;
				strategy_temp_normal_low =	<4520 10 1 0 0>;
				strategy_temp_normal_high =	<4520 10 1 0 0>;
				strategy_temp_warm = <4130 10 1 0 0>;
			};
		};

		vooc_charge_strategy {
			strategy_soc_0_to_50 {
				strategy_temp_little_cold =	<4150 3 0 0 0
								 4470 22 0 0 0
								 4480 20 1 0 0>;
				strategy_temp_cool = <4470 30 0 0 0
								 4480 20 1 0 0>;
				strategy_temp_little_cool =	<4510 30 0 0 0
								 4520 20 1 0 0>;
				strategy_temp_little_cool_high = <4510 30 0 0 0
								 4520 20 1 0 0>;
				strategy_temp_normal_low =	<4510 30 0 0 0
								 4520 20 1 0 0>;
				strategy_temp_normal_high =	<4510 30 0 0 0
								 4520 20 1 0 0>;
				strategy_temp_warm = <4120 26 0 0 0
								 4130 20 1 0 0>;
			};

			strategy_soc_0_to_50_mid {
				strategy_temp_little_cold =	<4150 30 0 0 0
								 4470 22 0 0 0
								 4480 20 1 0 0>;
				strategy_temp_cool = <4470 30 0 0 0
								 4480 20 1 0 0>;
				strategy_temp_little_cool =	<4510 30 0 0 0
								 4520 20 1 0 0>;
				strategy_temp_little_cool_high = <4510 30 0 0 0
								 4520 20 1 0 0>;
				strategy_temp_normal_low =	<4510 30 0 0 0
								 4520 20 1 0 0>;
				strategy_temp_normal_high =	<4510 30 0 0 0
								 4520 20 1 0 0>;
				strategy_temp_warm = <4120 26 0 0 0
								 4130 22 1 0 0>;
			};

			strategy_soc_0_to_50_high {
				strategy_temp_little_cold =	<4150 30 0 0 0
								 4470 22 0 0 0
								 4480 20 1 0 0>;
				strategy_temp_cool = <4470 30 0 0 0
								 4480 20 1 0 0>;
				strategy_temp_little_cool =	<4510 30 0 0 0
								 4520 20 1 0 0>;
				strategy_temp_little_cool_high = <4510 30 0 0 0
								 4520 20 1 0 0>;
				strategy_temp_normal_low =	<4510 30 0 0 0
								 4520 20 1 0 0>;
				strategy_temp_normal_high =	<4510 30 0 0 0
								 4520 20 1 0 0>;
				strategy_temp_warm = <4120 26 1 0 0
								 4130 20 1 0 0>;
			};

			strategy_soc_50_to_75 {
				strategy_temp_little_cold =	<4480 20 1 0 0>;
				strategy_temp_cool =	<4470 30 0 0 0
								 4480 20 1 0 0>;
				strategy_temp_little_cool =	<4510 30 0 0 0
								 4520 20 1 0 0>;
				strategy_temp_little_cool_high = <4510 30 0 0 0
								 4520 20 1 0 0>;
				strategy_temp_normal_low = <4510 30 0 0 0
								 4520 20 1 0 0>;
				strategy_temp_normal_high =	<4510 30 0 0 0
								 4520 20 1 0 0>;
				strategy_temp_warm = <4130 20 1 0 0>;
			};

			strategy_soc_75_to_85 {
				strategy_temp_little_cold =	<4480 20 1 0 0>;
				strategy_temp_cool = <4480 20 1 0 0>;
				strategy_temp_little_cool =	<4510 30 0 0 0
								 4520 20 1 0 0>;
				strategy_temp_little_cool_high = <4510 30 0 0 0
								 4520 20 1 0 0>;
				strategy_temp_normal_low = <4510 30 0 0 0
								 4520 20 1 0 0>;
				strategy_temp_normal_high =	<4510 30 0 0 0
								 4520 20 1 0 0>;
				strategy_temp_warm = <4130 20 1 0 0>;
			};

			strategy_soc_85_to_90 {
				strategy_temp_little_cold =	<4480 20 1 0 0>;
				strategy_temp_cool = <4480 20 1 0 0>;
				strategy_temp_little_cool =	<4520 20 1 0 0>;
				strategy_temp_little_cool_high = <4520 20 1 0 0>;
				strategy_temp_normal_low =	<4520 20 1 0 0>;
				strategy_temp_normal_high =	<4520 20 1 0 0>;
				strategy_temp_warm = <4130 20 1 0 0>;
			};
		};
		oplus_sc8547_cp: oplus,sc8547_cp {
			oplus,ic_type = <OPLUS_CHG_IC_CP>;
			oplus,ic_index = <0>;
			oplus,ic_func_group = <&sc8547_cp_groups>;
		};
	};
};


#include "oplus-chg-24705-pps.dtsi"
